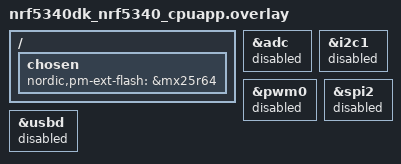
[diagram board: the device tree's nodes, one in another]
/*
 * SPDX-FileCopyrightText: 2022 Project CHIP Authors
 *
 * SPDX-License-Identifier: Apache-2.0
 */

/ {
	chosen {
		nordic,pm-ext-flash = &mx25r64;
	};
};

/* Disable unused peripherals to reduce power consumption */
&adc {
	status = "disabled";
};
&i2c1 {
	status = "disabled";
};
&pwm0 {
	status = "disabled";
};
&spi2 {
	status = "disabled";
};
&usbd {
	status = "disabled";
};
